# S32K324_M7 register map
Vendor: NXP Semiconductors; File version: 1.1
CPU: CM7 r0p1, little endian, MPU, FPU, VTOR, 4 interrupt priority bits
Registers are 32-bit, read-write, reset 0x0 unless marked. A register's access mark holds for its fields unless they carry their own. Offsets are from the block's base; [hi:lo] are bit positions; {n}, {i} and the like mark numbered series; 'fields as' and 'values as' point back to an identical list.

## ERM
Base 0x4025C000
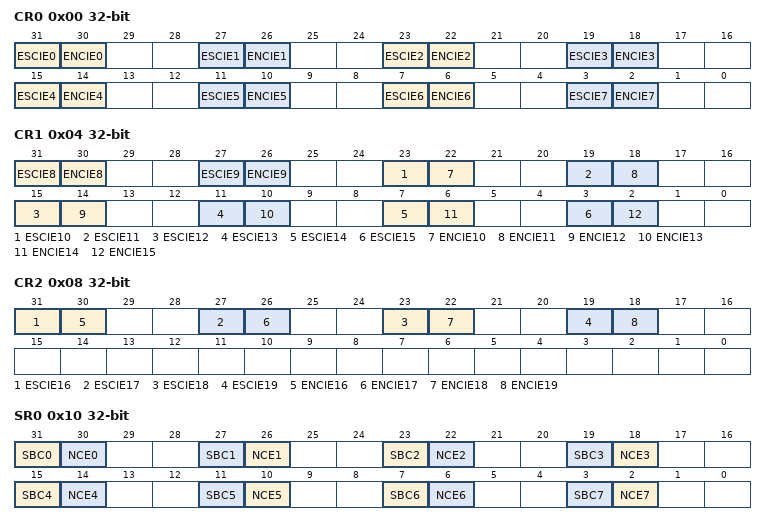
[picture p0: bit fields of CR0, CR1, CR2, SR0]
0x00 CR0 — ERM Configuration Register 0
  [31-4n] ESCIE{n} (n=0..7)
    0=DISABLE (Interrupt notification of Memory {n} single-bit correction events is disabled.); 1=ENABLE (Interrupt notification of Memory {n} single-bit correction events is enabled.)
  [30-4n] ENCIE{n} (n=0..7)
    0=DISABLE (Interrupt notification of Memory {n} non-correctable error events is disabled.); 1=ENABLE (Interrupt notification of Memory {n} non-correctable error events is enabled.)
0x04 CR1 — ERM Configuration Register 1
  [63-4n] ESCIE{n} (n=8..15)
    values as CR0.ESCIE0
  [62-4n] ENCIE{n} (n=8..15)
    values as CR0.ENCIE0
0x08 CR2 — ERM Configuration Register 2
  [95-4n] ESCIE{n} (n=16..19)
    values as CR0.ESCIE0
  [94-4n] ENCIE{n} (n=16..19)
    values as CR0.ENCIE0
0x10 SR0 write-1-clears — ERM Status Register 0
  [31-4n] SBC{n} write-1-clears (n=0..4)
    0=NO_EVENT (No single-bit correction event on Memory {n} detected.); 1=EVENT (Single-bit correction event on Memory {n} detected.)
  [30-4n] NCE{n} write-1-clears (n=0..7)
    0=NO_ERROR (No non-correctable error event on Memory {n} detected.); 1=ERROR (Non-correctable error event on Memory {n} detected.)
  [11] SBC5 write-1-clears
    0=NO_EVENT (No single-bit correction event on Memory 5 detected.); 1=CORR_EVENT (Single-bit correction event on Memory 5 detected.)
  [7] SBC6 write-1-clears
    0=NO_EVENT (No single-bit correction event on Memory 6 detected.); 1=EVENT (Single-bit correction event on Memory 6 detected.)
  [3] SBC7 write-1-clears
    0=NO_EVENT (No single-bit correction event on Memory 7 detected.); 1=EVENT (Single-bit correction event on Memory 7 detected.)
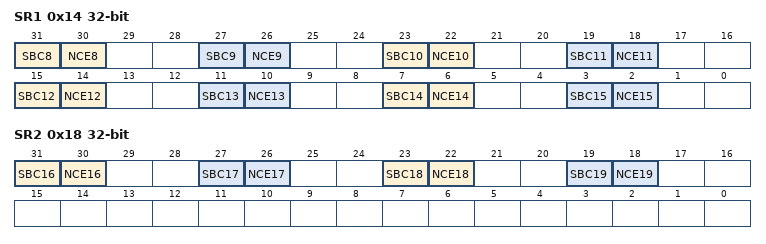
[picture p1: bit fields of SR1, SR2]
0x14 SR1 write-1-clears — ERM Status Register 1
  [63-4n] SBC{n} write-1-clears (n=8..15)
    values as SR0.SBC0
  [62-4n] NCE{n} write-1-clears (n=8..15)
    values as SR0.NCE0
0x18 SR2 write-1-clears — ERM Status Register 2
  [95-4n] SBC{n} write-1-clears (n=16..19)
    values as SR0.SBC0
  [94-4n] NCE{n} write-1-clears (n=16..19)
    values as SR0.NCE0
0x100 EAR0 ro — ERM Memory 0 Error Address Register
  [31:0] EAR
0x104 SYN0 ro — ERM Memory 0 Syndrome Register
  [31:24] SYNDROME
{0x108+0x10*i} CORR_ERR_CNT{i} (i=0..19) — ERM Memory {i} Correctable Error Count Register
  [7:0] COUNT — Memory n Correctable Error Count
0x110 EAR1 ro — ERM Memory 1 Error Address Register
  [31:0] EAR
0x114 SYN1 ro — ERM Memory 1 Syndrome Register
  [31:24] SYNDROME
{0x100+0x10*i} EAR{i} ro (i=10..19) — ERM Memory {i} Error Address Register
  [31:0] EAR
{0x104+0x10*i} SYN{i} ro (i=10..16) — ERM Memory {i} Syndrome Register
  [31:24] SYNDROME

## PRAMC_0 — PRAMC
Base 0x40264000
Same registers: PRAMC_1 0x40464000
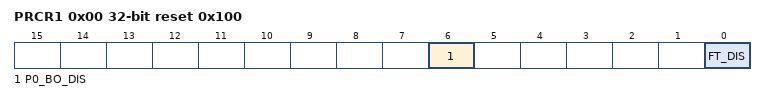
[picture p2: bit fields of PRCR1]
0x00 PRCR1 reset 0x100 — Platform RAM Configuration register 1
  [6] P0_BO_DIS — Port p0 read burst optimization disable.
    0=OPT_YES (64-bit WRP4 read bursts are optimized such that the controller returns a 2-1-1-1 response when PRCR1[FT_DIS ]=1); 1=OPT_NO (64-bit WRP4 read bursts are not optimized; the controller returns a 2-2-2-2 response when PRCR1[FT_DIS ]=1)
  [0] FT_DIS — Flow-through disabled
    0=DIRECT (RAM read data is passed directly to the system bus, incurring no additional latency); 1=REGISTER (RAM read data is registered prior to returning on the system bus, incurring one extra cycle of latency)

## SWT_0 — SWT
Base 0x40270000
Same registers: SWT_1 0x4046C000
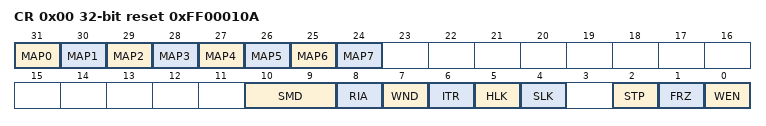
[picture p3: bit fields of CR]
0x00 CR reset 0xFF00010A — Control
  [31-n] MAP{n} (n=0..7) — Master Access Protection {n}
    0=disabled (Access disabled); 1=enabled (Access enabled)
  [10:9] SMD — Service Mode
    0=Fixed Service Sequence; 1=Keyed Service Sequence
  [8] RIA — Reset on Invalid Access
    0=bus_error (Generate a bus error); 1=reset_req (Generate a bus error and reset request)
  [7] WND — Window Mode
    0=Regular mode; 1=windowed (Window mode)
  [6] ITR — Interrupt Then Reset Request
    0=reset_req (Generate a reset request on a timeout); 1=interrupt (Generate an interrupt on an initial timeout; generate a reset request on a second consecutive timeout)
  [5] HLK — Hard Lock
    0=rw (CR, TO, WN, and SK are read/write registers if SLK is also 0); 1=ro (CR, TO, WN, and SK are read-only registers)
  [4] SLK — Soft Lock
    0=rw (CR, TO, WN, and SK are read/write registers if HLK is also 0); 1=ro (CR, TO, WN, and SK are read-only registers)
  [2] STP — Stop Mode Control
    0=continues (Timer continues); 1=stopped (Timer stops)
  [1] FRZ — Debug Mode Control
    0=continues (Timer continues); 1=stopped (Timer stops)
  [0] WEN — Watchdog Enable
    0=disabled; 1=enabled
0x04 IR write-1-clears — Interrupt
  [0] TIF write-1-clears — Timeout Interrupt Flag
    0=no_irq (No interrupt request); 1=irq (Interrupt request due to an initial timeout)
0x08 TO reset 0x320 — Timeout
  [31:0] WTO — Watchdog Timeout
0x0C WN — Window
  [31:0] WST — Window Start Value
0x10 SR — Service
  [15:0] WSC — Watchdog Service Code
0x14 CO ro — Counter Output
  [31:0] CNT — Watchdog Count
0x18 SK — Service Key
  [15:0] SK
0x1C RRR write-1-clears — Event Request
  [0] RRF write-1-clears — Reset Request Flag
    0=no (No reset request); 1=any (Any reset request initiated)
